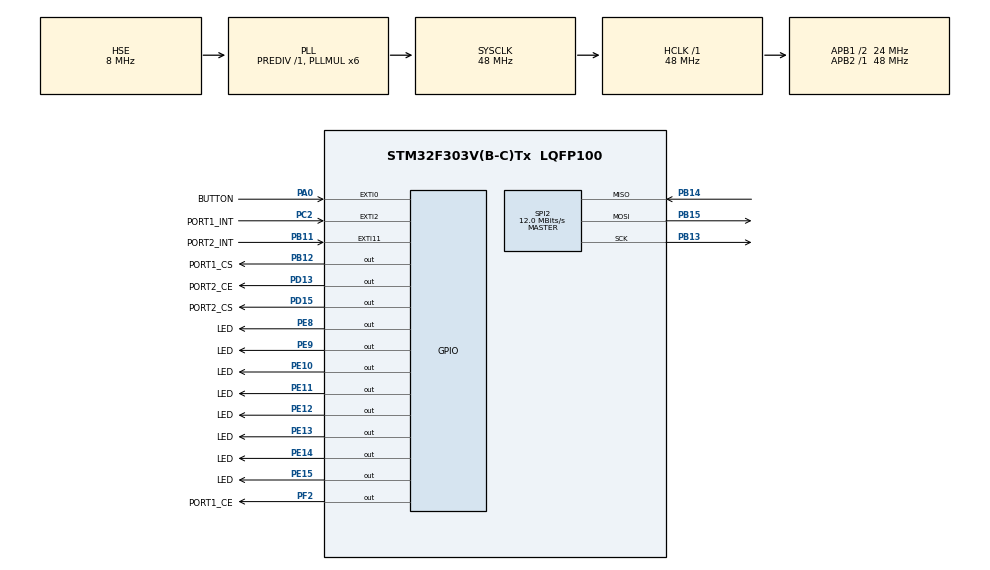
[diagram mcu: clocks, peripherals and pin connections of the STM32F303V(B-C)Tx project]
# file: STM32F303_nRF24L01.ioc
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Dma.Request0=SPI2_RX
Dma.Request1=SPI2_TX
Dma.SPI2_RX.0.Direction=DMA_PERIPH_TO_MEMORY
Dma.SPI2_RX.0.Instance=DMA1_Channel4
Dma.SPI2_RX.0.MemDataAlignment=DMA_MDATAALIGN_BYTE
Dma.SPI2_RX.0.MemInc=DMA_MINC_ENABLE
Dma.SPI2_RX.0.Mode=DMA_NORMAL
Dma.SPI2_RX.0.PeriphDataAlignment=DMA_PDATAALIGN_BYTE
Dma.SPI2_RX.0.PeriphInc=DMA_PINC_DISABLE
Dma.SPI2_RX.0.Priority=DMA_PRIORITY_LOW
Dma.SPI2_TX.1.Direction=DMA_MEMORY_TO_PERIPH
Dma.SPI2_TX.1.Instance=DMA1_Channel5
Dma.SPI2_TX.1.MemDataAlignment=DMA_MDATAALIGN_BYTE
Dma.SPI2_TX.1.MemInc=DMA_MINC_ENABLE
Dma.SPI2_TX.1.Mode=DMA_NORMAL
Dma.SPI2_TX.1.PeriphDataAlignment=DMA_PDATAALIGN_BYTE
Dma.SPI2_TX.1.PeriphInc=DMA_PINC_DISABLE
Dma.SPI2_TX.1.Priority=DMA_PRIORITY_LOW
FREERTOS.HEAP_NUMBER=4
FREERTOS.INCLUDE_uxTaskGetStackHighWaterMark=1
FREERTOS.Tasks01=applicationTask,0,256,applicationTaskFunction,As weak,NULL,Dynamic,NULL,NULL
FREERTOS.configMAX_PRIORITIES=4
FREERTOS.configMINIMAL_STACK_SIZE=256
FREERTOS.configTOTAL_HEAP_SIZE=16384
FREERTOS.configUSE_PREEMPTION=1
Mcu.Family=STM32F3
Mcu.Name=STM32F303V(B-C)Tx
Mcu.Package=LQFP100
NVIC.DMA1_Channel4_IRQn=true\:5\:0\:false\:false\:true\:true
NVIC.DMA1_Channel5_IRQn=true\:5\:0\:false\:false\:true\:true
NVIC.EXTI0_IRQn=true\:5\:0\:false\:false\:true\:true
NVIC.EXTI15_10_IRQn=true\:5\:0\:false\:false\:true\:true
NVIC.EXTI2_TSC_IRQn=true\:5\:0\:false\:false\:true\:true
NVIC.PriorityGroup=NVIC_PRIORITYGROUP_4
NVIC.SPI2_IRQn=true\:5\:0\:false\:false\:true\:true
NVIC.TIM7_IRQn=true\:0\:0\:false\:false\:true\:false
NVIC.TimeBase=TIM7_IRQn
NVIC.TimeBaseIP=TIM7
PA0.GPIO_Label=BUTTON
PA0.GPIO_ModeDefaultEXTI=GPIO_MODE_IT_RISING
PA0.GPIO_PuPd=GPIO_PULLDOWN
PA0.Signal=GPXTI0
PB11.GPIO_Label=PORT2_INT
PB11.GPIO_ModeDefaultEXTI=GPIO_MODE_IT_FALLING
PB11.Signal=GPXTI11
PB12.GPIO_Label=PORT1_CS
PB12.PinState=GPIO_PIN_SET
PB12.Signal=GPIO_Output
PB13.GPIO_PuPd=GPIO_NOPULL
PB13.Mode=Full_Duplex_Master
PB13.Signal=SPI2_SCK
PB14.GPIO_PuPd=GPIO_NOPULL
PB14.Mode=Full_Duplex_Master
PB14.Signal=SPI2_MISO
PB15.GPIO_PuPd=GPIO_NOPULL
PB15.Mode=Full_Duplex_Master
PB15.Signal=SPI2_MOSI
PC2.GPIO_Label=PORT1_INT
PC2.GPIO_ModeDefaultEXTI=GPIO_MODE_IT_FALLING
PC2.Signal=GPXTI2
PD13.GPIO_Label=PORT2_CE
PD13.GPIO_PuPd=GPIO_NOPULL
PD13.GPIO_Speed=GPIO_SPEED_FREQ_LOW
PD13.PinState=GPIO_PIN_RESET
PD13.Signal=GPIO_Output
PD15.GPIO_Label=PORT2_CS
PD15.GPIO_PuPd=GPIO_NOPULL
PD15.GPIO_Speed=GPIO_SPEED_FREQ_LOW
PD15.PinState=GPIO_PIN_SET
PD15.Signal=GPIO_Output
PE10.GPIO_Label=LED
PE10.GPIO_ModeDefaultOutputPP=GPIO_MODE_OUTPUT_PP
PE10.GPIO_PuPd=GPIO_NOPULL
PE10.GPIO_Speed=GPIO_SPEED_FREQ_LOW
PE10.PinState=GPIO_PIN_RESET
PE10.Signal=GPIO_Output
PE11.GPIO_Label=LED
PE11.GPIO_ModeDefaultOutputPP=GPIO_MODE_OUTPUT_PP
PE11.GPIO_PuPd=GPIO_NOPULL
PE11.GPIO_Speed=GPIO_SPEED_FREQ_LOW
PE11.PinState=GPIO_PIN_RESET
PE11.Signal=GPIO_Output
PE12.GPIO_Label=LED
PE12.GPIO_ModeDefaultOutputPP=GPIO_MODE_OUTPUT_PP
PE12.GPIO_PuPd=GPIO_NOPULL
PE12.GPIO_Speed=GPIO_SPEED_FREQ_LOW
PE12.PinState=GPIO_PIN_RESET
PE12.Signal=GPIO_Output
PE13.GPIO_Label=LED
PE13.GPIO_ModeDefaultOutputPP=GPIO_MODE_OUTPUT_PP
PE13.GPIO_PuPd=GPIO_NOPULL
PE13.GPIO_Speed=GPIO_SPEED_FREQ_LOW
PE13.PinState=GPIO_PIN_RESET
PE13.Signal=GPIO_Output
PE14.GPIO_Label=LED
PE14.GPIO_ModeDefaultOutputPP=GPIO_MODE_OUTPUT_PP
PE14.GPIO_PuPd=GPIO_NOPULL
PE14.GPIO_Speed=GPIO_SPEED_FREQ_LOW
PE14.PinState=GPIO_PIN_RESET
PE14.Signal=GPIO_Output
PE15.GPIO_Label=LED
PE15.GPIO_ModeDefaultOutputPP=GPIO_MODE_OUTPUT_PP
PE15.GPIO_PuPd=GPIO_NOPULL
PE15.GPIO_Speed=GPIO_SPEED_FREQ_LOW
PE15.PinState=GPIO_PIN_RESET
PE15.Signal=GPIO_Output
PE8.GPIO_Label=LED
PE8.GPIO_ModeDefaultOutputPP=GPIO_MODE_OUTPUT_PP
PE8.GPIO_PuPd=GPIO_NOPULL
PE8.GPIO_Speed=GPIO_SPEED_FREQ_LOW
PE8.PinState=GPIO_PIN_RESET
PE8.Signal=GPIO_Output
PE9.GPIO_Label=LED
PE9.GPIO_ModeDefaultOutputPP=GPIO_MODE_OUTPUT_PP
PE9.GPIO_PuPd=GPIO_NOPULL
PE9.GPIO_Speed=GPIO_SPEED_FREQ_LOW
PE9.PinState=GPIO_PIN_RESET
PE9.Signal=GPIO_Output
PF0-OSC_IN.Mode=HSE-External-Clock-Source
PF0-OSC_IN.Signal=RCC_OSC_IN
PF2.GPIO_Label=PORT1_CE
PF2.Signal=GPIO_Output
ProjectManager.HeapSize=0x0
ProjectManager.StackSize=0x0
ProjectManager.TargetToolchain=TrueSTUDIO
RCC.AHBFreq_Value=48000000
RCC.APB1CLKDivider=RCC_HCLK_DIV2
RCC.APB1Freq_Value=24000000
RCC.APB1TimFreq_Value=48000000
RCC.APB2Freq_Value=48000000
RCC.APB2TimFreq_Value=48000000
RCC.CortexFreq_Value=48000000
RCC.HCLKFreq_Value=48000000
RCC.HSEUsed=1
RCC.HSE_VALUE=8000000
RCC.HSI_VALUE=8000000
RCC.LSE_VALUE=32768
RCC.PLLMUL=RCC_PLL_MUL6
RCC.PLLSourceARG=RCC_PLLSOURCE_HSE
RCC.PLLSourceVirtual=RCC_PLLSOURCE_HSE
RCC.SYSCLKFreq_VALUE=48000000
RCC.SYSCLKSourceVirtual=RCC_SYSCLKSOURCE_PLLCLK
RCC.USBFreq_Value=48000000
SPI2.BaudRatePrescaler=SPI_BAUDRATEPRESCALER_2
SPI2.CalculateBaudRate=12.0 MBits/s
SPI2.DataSize=SPI_DATASIZE_8BIT
SPI2.Direction=SPI_DIRECTION_2LINES
SPI2.FirstBit=SPI_FIRSTBIT_MSB
SPI2.Mode=SPI_MODE_MASTER
SPI2.NSSPMode=SPI_NSS_PULSE_DISABLE
SPI2.TIMode=SPI_TIMODE_DISABLE
SPI2.VirtualType=VM_MASTER
VP_FREERTOS_VS_ENABLE.Mode=Enabled
VP_SYS_VS_tim7.Mode=TIM7
board=STM32F3DISCOVERY

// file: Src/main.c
/**
  ******************************************************************************
  * File Name          : main.c
  * Description        : Main program body
  ******************************************************************************
  *
  * Copyright (c) 2017 STMicroelectronics International N.V.
  * All rights reserved.
  *
  * Redistribution and use in source and binary forms, with or without
  * modification, are permitted, provided that the following conditions are met:
  *
  * 1. Redistribution of source code must retain the above copyright notice,
  *    this list of conditions and the following disclaimer.
  * 2. Redistributions in binary form must reproduce the above copyright notice,
  *    this list of conditions and the following disclaimer in the documentation
  *    and/or other materials provided with the distribution.
  * 3. Neither the name of STMicroelectronics nor the names of other
  *    contributors to this software may be used to endorse or promote products
  *    derived from this software without specific written permission.
  * 4. This software, including modifications and/or derivative works of this
  *    software, must execute solely and exclusively on microcontroller or
  *    microprocessor devices manufactured by or for STMicroelectronics.
  * 5. Redistribution and use of this software other than as permitted under
  *    this license is void and will automatically terminate your rights under
  *    this license.
  *
  * THIS SOFTWARE IS PROVIDED BY STMICROELECTRONICS AND CONTRIBUTORS "AS IS"
  * AND ANY EXPRESS, IMPLIED OR STATUTORY WARRANTIES, INCLUDING, BUT NOT
  * LIMITED TO, THE IMPLIED WARRANTIES OF MERCHANTABILITY, FITNESS FOR A
  * PARTICULAR PURPOSE AND NON-INFRINGEMENT OF THIRD PARTY INTELLECTUAL PROPERTY
  * RIGHTS ARE DISCLAIMED TO THE FULLEST EXTENT PERMITTED BY LAW. IN NO EVENT
  * SHALL STMICROELECTRONICS OR CONTRIBUTORS BE LIABLE FOR ANY DIRECT, INDIRECT,
  * INCIDENTAL, SPECIAL, EXEMPLARY, OR CONSEQUENTIAL DAMAGES (INCLUDING, BUT NOT
  * LIMITED TO, PROCUREMENT OF SUBSTITUTE GOODS OR SERVICES; LOSS OF USE, DATA,
  * OR PROFITS; OR BUSINESS INTERRUPTION) HOWEVER CAUSED AND ON ANY THEORY OF
  * LIABILITY, WHETHER IN CONTRACT, STRICT LIABILITY, OR TORT (INCLUDING
  * NEGLIGENCE OR OTHERWISE) ARISING IN ANY WAY OUT OF THE USE OF THIS SOFTWARE,
  * EVEN IF ADVISED OF THE POSSIBILITY OF SUCH DAMAGE.
  *
  ******************************************************************************
  */
#include "main.h"
#include "stm32f3xx_hal.h"
#include "cmsis_os.h"

SPI_HandleTypeDef hspi2;
DMA_HandleTypeDef hdma_spi2_rx;
DMA_HandleTypeDef hdma_spi2_tx;

osThreadId applicationTaskHandle;

/* USER CODE BEGIN PV */
/* Private variables ---------------------------------------------------------*/

/* USER CODE END PV */

void SystemClock_Config(void);
void Error_Handler(void);
static void MX_GPIO_Init(void);
static void MX_DMA_Init(void);
static void MX_SPI2_Init(void);
void applicationTaskFunction(void const * argument);

/* USER CODE BEGIN PFP */
/* Private function prototypes -----------------------------------------------*/
void initializeApplication();
/* USER CODE END PFP */

int main(void)
{

  /* MCU Configuration----------------------------------------------------------*/

  /* Reset of all peripherals, Initializes the Flash interface and the Systick. */
  HAL_Init();

  /* Configure the system clock */
  SystemClock_Config();

  /* Initialize all configured peripherals */
  MX_GPIO_Init();
  MX_DMA_Init();
  MX_SPI2_Init();

  /* USER CODE BEGIN RTOS_TIMERS */
    initializeApplication();
  /* USER CODE END RTOS_TIMERS */

  /* Create the thread(s) */
  /* definition and creation of applicationTask */
  osThreadDef(applicationTask, applicationTaskFunction, osPriorityNormal, 0, 256);
  applicationTaskHandle = osThreadCreate(osThread(applicationTask), NULL);

  /* Start scheduler */
  osKernelStart();

  /* We should never get here as control is now taken by the scheduler */

  /* Infinite loop */
    while (1) {

    }

}

/** System Clock Configuration
*/
void SystemClock_Config(void)
{

  RCC_OscInitTypeDef RCC_OscInitStruct;
  RCC_ClkInitTypeDef RCC_ClkInitStruct;

    /**Initializes the CPU, AHB and APB busses clocks
    */
  RCC_OscInitStruct.OscillatorType = RCC_OSCILLATORTYPE_HSE;
  RCC_OscInitStruct.HSEState = RCC_HSE_BYPASS;
  RCC_OscInitStruct.HSEPredivValue = RCC_HSE_PREDIV_DIV1;
  RCC_OscInitStruct.HSIState = RCC_HSI_ON;
  RCC_OscInitStruct.PLL.PLLState = RCC_PLL_ON;
  RCC_OscInitStruct.PLL.PLLSource = RCC_PLLSOURCE_HSE;
  RCC_OscInitStruct.PLL.PLLMUL = RCC_PLL_MUL6;
  if (HAL_RCC_OscConfig(&RCC_OscInitStruct) != HAL_OK)
  {
    Error_Handler();
  }

    /**Initializes the CPU, AHB and APB busses clocks
    */
  RCC_ClkInitStruct.ClockType = RCC_CLOCKTYPE_HCLK|RCC_CLOCKTYPE_SYSCLK
                              |RCC_CLOCKTYPE_PCLK1|RCC_CLOCKTYPE_PCLK2;
  RCC_ClkInitStruct.SYSCLKSource = RCC_SYSCLKSOURCE_PLLCLK;
  RCC_ClkInitStruct.AHBCLKDivider = RCC_SYSCLK_DIV1;
  RCC_ClkInitStruct.APB1CLKDivider = RCC_HCLK_DIV2;
  RCC_ClkInitStruct.APB2CLKDivider = RCC_HCLK_DIV1;

  if (HAL_RCC_ClockConfig(&RCC_ClkInitStruct, FLASH_LATENCY_1) != HAL_OK)
  {
    Error_Handler();
  }

    /**Configure the Systick interrupt time
    */
  HAL_SYSTICK_Config(HAL_RCC_GetHCLKFreq()/1000);

    /**Configure the Systick
    */
  HAL_SYSTICK_CLKSourceConfig(SYSTICK_CLKSOURCE_HCLK);

  /* SysTick_IRQn interrupt configuration */
  HAL_NVIC_SetPriority(SysTick_IRQn, 15, 0);
}

/* SPI2 init function */
static void MX_SPI2_Init(void)
{

  hspi2.Instance = SPI2;
  hspi2.Init.Mode = SPI_MODE_MASTER;
  hspi2.Init.Direction = SPI_DIRECTION_2LINES;
  hspi2.Init.DataSize = SPI_DATASIZE_8BIT;
  hspi2.Init.CLKPolarity = SPI_POLARITY_LOW;
  hspi2.Init.CLKPhase = SPI_PHASE_1EDGE;
  hspi2.Init.NSS = SPI_NSS_SOFT;
  hspi2.Init.BaudRatePrescaler = SPI_BAUDRATEPRESCALER_2;
  hspi2.Init.FirstBit = SPI_FIRSTBIT_MSB;
  hspi2.Init.TIMode = SPI_TIMODE_DISABLE;
  hspi2.Init.CRCCalculation = SPI_CRCCALCULATION_DISABLE;
  hspi2.Init.CRCPolynomial = 7;
  hspi2.Init.CRCLength = SPI_CRC_LENGTH_DATASIZE;
  hspi2.Init.NSSPMode = SPI_NSS_PULSE_DISABLE;
  if (HAL_SPI_Init(&hspi2) != HAL_OK)
  {
    Error_Handler();
  }

}

static void MX_DMA_Init(void)
{
  /* DMA controller clock enable */
  __HAL_RCC_DMA1_CLK_ENABLE();

  /* DMA interrupt init */
  /* DMA1_Channel4_IRQn interrupt configuration */
  HAL_NVIC_SetPriority(DMA1_Channel4_IRQn, 5, 0);
  HAL_NVIC_EnableIRQ(DMA1_Channel4_IRQn);
  /* DMA1_Channel5_IRQn interrupt configuration */
  HAL_NVIC_SetPriority(DMA1_Channel5_IRQn, 5, 0);
  HAL_NVIC_EnableIRQ(DMA1_Channel5_IRQn);

}

/** Configure pins as
        * Analog
        * Input
        * Output
        * EVENT_OUT
        * EXTI
*/
static void MX_GPIO_Init(void)
{

  GPIO_InitTypeDef GPIO_InitStruct;

  /* GPIO Ports Clock Enable */
  __HAL_RCC_GPIOF_CLK_ENABLE();
  __HAL_RCC_GPIOC_CLK_ENABLE();
  __HAL_RCC_GPIOA_CLK_ENABLE();
  __HAL_RCC_GPIOE_CLK_ENABLE();
  __HAL_RCC_GPIOB_CLK_ENABLE();
  __HAL_RCC_GPIOD_CLK_ENABLE();

  /*Configure GPIO pin Output Level */
  HAL_GPIO_WritePin(PORT1_CE_GPIO_Port, PORT1_CE_Pin, GPIO_PIN_RESET);

  /*Configure GPIO pin Output Level */
  HAL_GPIO_WritePin(GPIOE, LED_Pin|LEDE9_Pin|LEDE10_Pin|LEDE11_Pin
                          |LEDE12_Pin|LEDE13_Pin|LEDE14_Pin|LEDE15_Pin, GPIO_PIN_RESET);

  /*Configure GPIO pin Output Level */
  HAL_GPIO_WritePin(PORT1_CS_GPIO_Port, PORT1_CS_Pin, GPIO_PIN_SET);

  /*Configure GPIO pin Output Level */
  HAL_GPIO_WritePin(PORT2_CE_GPIO_Port, PORT2_CE_Pin, GPIO_PIN_RESET);

  /*Configure GPIO pin Output Level */
  HAL_GPIO_WritePin(PORT2_CS_GPIO_Port, PORT2_CS_Pin, GPIO_PIN_SET);

  /*Configure GPIO pin : PORT1_INT_Pin */
  GPIO_InitStruct.Pin = PORT1_INT_Pin;
  GPIO_InitStruct.Mode = GPIO_MODE_IT_FALLING;
  GPIO_InitStruct.Pull = GPIO_NOPULL;
  HAL_GPIO_Init(PORT1_INT_GPIO_Port, &GPIO_InitStruct);

  /*Configure GPIO pin : PORT1_CE_Pin */
  GPIO_InitStruct.Pin = PORT1_CE_Pin;
  GPIO_InitStruct.Mode = GPIO_MODE_OUTPUT_PP;
  GPIO_InitStruct.Pull = GPIO_NOPULL;
  GPIO_InitStruct.Speed = GPIO_SPEED_FREQ_LOW;
  HAL_GPIO_Init(PORT1_CE_GPIO_Port, &GPIO_InitStruct);

  /*Configure GPIO pin : BUTTON_Pin */
  GPIO_InitStruct.Pin = BUTTON_Pin;
  GPIO_InitStruct.Mode = GPIO_MODE_IT_RISING;
  GPIO_InitStruct.Pull = GPIO_PULLDOWN;
  HAL_GPIO_Init(BUTTON_GPIO_Port, &GPIO_InitStruct);

  /*Configure GPIO pins : LED_Pin LEDE9_Pin LEDE10_Pin LEDE11_Pin
                           LEDE12_Pin LEDE13_Pin LEDE14_Pin LEDE15_Pin */
  GPIO_InitStruct.Pin = LED_Pin|LEDE9_Pin|LEDE10_Pin|LEDE11_Pin
                          |LEDE12_Pin|LEDE13_Pin|LEDE14_Pin|LEDE15_Pin;
  GPIO_InitStruct.Mode = GPIO_MODE_OUTPUT_PP;
  GPIO_InitStruct.Pull = GPIO_NOPULL;
  GPIO_InitStruct.Speed = GPIO_SPEED_FREQ_LOW;
  HAL_GPIO_Init(GPIOE, &GPIO_InitStruct);

  /*Configure GPIO pin : PORT2_INT_Pin */
  GPIO_InitStruct.Pin = PORT2_INT_Pin;
  GPIO_InitStruct.Mode = GPIO_MODE_IT_FALLING;
  GPIO_InitStruct.Pull = GPIO_NOPULL;
  HAL_GPIO_Init(PORT2_INT_GPIO_Port, &GPIO_InitStruct);

  /*Configure GPIO pin : PORT1_CS_Pin */
  GPIO_InitStruct.Pin = PORT1_CS_Pin;
  GPIO_InitStruct.Mode = GPIO_MODE_OUTPUT_PP;
  GPIO_InitStruct.Pull = GPIO_NOPULL;
  GPIO_InitStruct.Speed = GPIO_SPEED_FREQ_LOW;
  HAL_GPIO_Init(PORT1_CS_GPIO_Port, &GPIO_InitStruct);

  /*Configure GPIO pins : PORT2_CE_Pin PORT2_CS_Pin */
  GPIO_InitStruct.Pin = PORT2_CE_Pin|PORT2_CS_Pin;
  GPIO_InitStruct.Mode = GPIO_MODE_OUTPUT_PP;
  GPIO_InitStruct.Pull = GPIO_NOPULL;
  GPIO_InitStruct.Speed = GPIO_SPEED_FREQ_LOW;
  HAL_GPIO_Init(GPIOD, &GPIO_InitStruct);

  /* EXTI interrupt init*/
  HAL_NVIC_SetPriority(EXTI0_IRQn, 5, 0);
  HAL_NVIC_EnableIRQ(EXTI0_IRQn);

  HAL_NVIC_SetPriority(EXTI2_TSC_IRQn, 5, 0);
  HAL_NVIC_EnableIRQ(EXTI2_TSC_IRQn);

  HAL_NVIC_SetPriority(EXTI15_10_IRQn, 5, 0);
  HAL_NVIC_EnableIRQ(EXTI15_10_IRQn);

}

/* applicationTaskFunction function */
__weak void applicationTaskFunction(void const * argument)
{

    for (;;) {
        osDelay(1);
    }
}

void HAL_TIM_PeriodElapsedCallback(TIM_HandleTypeDef *htim)
{
  if (htim->Instance == TIM7) {
    HAL_IncTick();
  }
}

void Error_Handler(void)
{
    while (1) {
    }
}

/************************ (C) COPYRIGHT STMicroelectronics *****END OF FILE****/

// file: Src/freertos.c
/**
  ******************************************************************************
  * File Name          : freertos.c
  * Description        : Code for freertos applications
  ******************************************************************************
  *
  * Copyright (c) 2017 STMicroelectronics International N.V.
  * All rights reserved.
  *
  * Redistribution and use in source and binary forms, with or without
  * modification, are permitted, provided that the following conditions are met:
  *
  * 1. Redistribution of source code must retain the above copyright notice,
  *    this list of conditions and the following disclaimer.
  * 2. Redistributions in binary form must reproduce the above copyright notice,
  *    this list of conditions and the following disclaimer in the documentation
  *    and/or other materials provided with the distribution.
  * 3. Neither the name of STMicroelectronics nor the names of other
  *    contributors to this software may be used to endorse or promote products
  *    derived from this software without specific written permission.
  * 4. This software, including modifications and/or derivative works of this
  *    software, must execute solely and exclusively on microcontroller or
  *    microprocessor devices manufactured by or for STMicroelectronics.
  * 5. Redistribution and use of this software other than as permitted under
  *    this license is void and will automatically terminate your rights under
  *    this license.
  *
  * THIS SOFTWARE IS PROVIDED BY STMICROELECTRONICS AND CONTRIBUTORS "AS IS"
  * AND ANY EXPRESS, IMPLIED OR STATUTORY WARRANTIES, INCLUDING, BUT NOT
  * LIMITED TO, THE IMPLIED WARRANTIES OF MERCHANTABILITY, FITNESS FOR A
  * PARTICULAR PURPOSE AND NON-INFRINGEMENT OF THIRD PARTY INTELLECTUAL PROPERTY
  * RIGHTS ARE DISCLAIMED TO THE FULLEST EXTENT PERMITTED BY LAW. IN NO EVENT
  * SHALL STMICROELECTRONICS OR CONTRIBUTORS BE LIABLE FOR ANY DIRECT, INDIRECT,
  * INCIDENTAL, SPECIAL, EXEMPLARY, OR CONSEQUENTIAL DAMAGES (INCLUDING, BUT NOT
  * LIMITED TO, PROCUREMENT OF SUBSTITUTE GOODS OR SERVICES; LOSS OF USE, DATA,
  * OR PROFITS; OR BUSINESS INTERRUPTION) HOWEVER CAUSED AND ON ANY THEORY OF
  * LIABILITY, WHETHER IN CONTRACT, STRICT LIABILITY, OR TORT (INCLUDING
  * NEGLIGENCE OR OTHERWISE) ARISING IN ANY WAY OUT OF THE USE OF THIS SOFTWARE,
  * EVEN IF ADVISED OF THE POSSIBILITY OF SUCH DAMAGE.
  *
  ******************************************************************************
  */

#include "FreeRTOS.h"
#include "task.h"
#include "cmsis_os.h"

osThreadId defaultTaskHandle;

void StartDefaultTask(void const * argument);

void MX_FREERTOS_Init(void); /* (MISRA C 2004 rule 8.1) */

/* Hook prototypes */

/* Init FreeRTOS */

void MX_FREERTOS_Init(void) {

  /* Create the thread(s) */
  /* definition and creation of defaultTask */
  osThreadDef(defaultTask, StartDefaultTask, osPriorityIdle, 0, 128);
  defaultTaskHandle = osThreadCreate(osThread(defaultTask), NULL);

}

/* StartDefaultTask function */
void StartDefaultTask(void const * argument)
{

  for(;;)
  {
    osDelay(1);
  }
}

/************************ (C) COPYRIGHT STMicroelectronics *****END OF FILE****/
